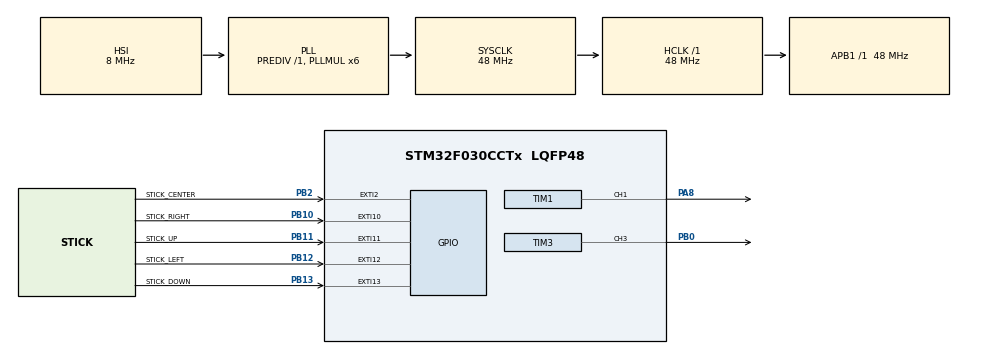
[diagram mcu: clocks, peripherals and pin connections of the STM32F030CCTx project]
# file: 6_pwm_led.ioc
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Mcu.Family=STM32F0
Mcu.Name=STM32F030CCTx
Mcu.Package=LQFP48
NVIC.EXTI2_3_IRQn=true\:0\:0\:false\:false\:true\:true\:true\:true
NVIC.EXTI4_15_IRQn=true\:0\:0\:false\:false\:true\:true\:true\:true
PA8.Signal=S_TIM1_CH1
PB0.Signal=S_TIM3_CH3
PB10.GPIO_Label=STICK_RIGHT
PB10.Signal=GPXTI10
PB11.GPIO_Label=STICK_UP
PB11.Signal=GPXTI11
PB12.GPIO_Label=STICK_LEFT
PB12.Signal=GPXTI12
PB13.GPIO_Label=STICK_DOWN
PB13.Signal=GPXTI13
PB2.GPIO_Label=STICK_CENTER
PB2.Signal=GPXTI2
ProjectManager.HeapSize=0x200
ProjectManager.StackSize=0x400
ProjectManager.TargetToolchain=CMake
RCC.AHBFreq_Value=48000000
RCC.APB1Freq_Value=48000000
RCC.APB1TimFreq_Value=48000000
RCC.HCLKFreq_Value=48000000
RCC.PLLMUL=RCC_PLL_MUL6
RCC.SYSCLKFreq_VALUE=48000000
RCC.SYSCLKSource=RCC_SYSCLKSOURCE_PLLCLK
SH.S_TIM1_CH1.0=TIM1_CH1,PWM Generation1 CH1
SH.S_TIM3_CH3.0=TIM3_CH3,PWM Generation3 CH3
TIM1.Channel-PWM\ Generation1\ CH1=TIM_CHANNEL_1
TIM3.Channel-PWM\ Generation3\ CH3=TIM_CHANNEL_3
TIM3.Period=665
TIM3.Prescaler=3
TIM3.Pulse-PWM\ Generation3\ CH3=665
VP_TIM3_VS_ClockSourceINT.Mode=Internal
board=custom

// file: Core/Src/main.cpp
/* USER CODE BEGIN Header */
/**
  ******************************************************************************
  * @file           : main.c
  * @brief          : Main program body
  ******************************************************************************
  * @attention
  *
  * Copyright (c) 2024 STMicroelectronics.
  * All rights reserved.
  *
  * This software is licensed under terms that can be found in the LICENSE file
  * in the root directory of this software component.
  * If no LICENSE file comes with this software, it is provided AS-IS.
  *
  ******************************************************************************
  */
/* USER CODE END Header */
#include "main.h"
#include "led_dimmer.h"

TIM_HandleTypeDef htim1;
TIM_HandleTypeDef htim3;

/* USER CODE BEGIN PV */
TIM_OC_InitTypeDef sConfigOC;
/* USER CODE END PV */

void SystemClock_Config(void);
static void MX_GPIO_Init(void);
static void MX_TIM1_Init(void);
static void MX_TIM3_Init(void);

int main(void)
{

  /* MCU Configuration--------------------------------------------------------*/

  /* Reset of all peripherals, Initializes the Flash interface and the Systick. */
  HAL_Init();

  /* Configure the system clock */
  SystemClock_Config();

  /* Initialize all configured peripherals */
  MX_GPIO_Init();
  MX_TIM1_Init();
  MX_TIM3_Init();
  /* USER CODE BEGIN 2 */
  // start PWM
  if (HAL_TIM_PWM_Start(&htim3, TIM_CHANNEL_3) != HAL_OK)
      Error_Handler();
  if (HAL_TIM_PWM_Start(&htim1, TIM_CHANNEL_2) != HAL_OK)
      Error_Handler();
  /* USER CODE END 2 */

  /* Infinite loop */
  /* USER CODE BEGIN WHILE */

  /*
   * For lab testing, set lab_mode to true
   * To change the duty cycle to n %, set a breakpoint at the while loop below this comment and modify
   * config->Pulse to (n / 100)*665 when the program is running.
   * Whithin CLion, this can be done by selecting the Pulse field and pressing F2.
   * Resume the program and wait 2 seconds to apply the new value.
  */
   volatile TIM_OC_InitTypeDef * volatile config = &sConfigOC;
   bool lab_mode = false;

  while (1)
  {
    /* USER CODE END WHILE */
    if(lab_mode) {
        HAL_Delay(2000);
        if (HAL_TIM_OC_ConfigChannel(&htim1, &sConfigOC, TIM_CHANNEL_2) != HAL_OK)
            Error_Handler();
    } else {
        // the mode is controlled and changed with the interrupt handler
        if(currentMode == 1) {
            auto_brightness();
        } else if(currentMode == 2) {
            heartbeat();
        }
    }

  }
}

void SystemClock_Config(void)
{
  RCC_OscInitTypeDef RCC_OscInitStruct = {0};
  RCC_ClkInitTypeDef RCC_ClkInitStruct = {0};

  /** Initializes the RCC Oscillators according to the specified parameters
  * in the RCC_OscInitTypeDef structure.
  */
  RCC_OscInitStruct.OscillatorType = RCC_OSCILLATORTYPE_HSI;
  RCC_OscInitStruct.HSIState = RCC_HSI_ON;
  RCC_OscInitStruct.HSICalibrationValue = RCC_HSICALIBRATION_DEFAULT;
  RCC_OscInitStruct.PLL.PLLState = RCC_PLL_ON;
  RCC_OscInitStruct.PLL.PLLSource = RCC_PLLSOURCE_HSI;
  RCC_OscInitStruct.PLL.PLLMUL = RCC_PLL_MUL6;
  RCC_OscInitStruct.PLL.PREDIV = RCC_PREDIV_DIV1;
  if (HAL_RCC_OscConfig(&RCC_OscInitStruct) != HAL_OK)
  {
    Error_Handler();
  }

  /** Initializes the CPU, AHB and APB buses clocks
  */
  RCC_ClkInitStruct.ClockType = RCC_CLOCKTYPE_HCLK|RCC_CLOCKTYPE_SYSCLK
                              |RCC_CLOCKTYPE_PCLK1;
  RCC_ClkInitStruct.SYSCLKSource = RCC_SYSCLKSOURCE_PLLCLK;
  RCC_ClkInitStruct.AHBCLKDivider = RCC_SYSCLK_DIV1;
  RCC_ClkInitStruct.APB1CLKDivider = RCC_HCLK_DIV1;

  if (HAL_RCC_ClockConfig(&RCC_ClkInitStruct, FLASH_LATENCY_1) != HAL_OK)
  {
    Error_Handler();
  }
}

static void MX_TIM1_Init(void)
{

  TIM_ClockConfigTypeDef sClockSourceConfig = {0};
  TIM_MasterConfigTypeDef sMasterConfig = {0};
  //TIM_OC_InitTypeDef sConfigOC = {0};
  TIM_BreakDeadTimeConfigTypeDef sBreakDeadTimeConfig = {0};

  htim1.Instance = TIM1;
  htim1.Init.Prescaler = 3;
  htim1.Init.CounterMode = TIM_COUNTERMODE_UP;
  htim1.Init.Period = 665;
  htim1.Init.ClockDivision = TIM_CLOCKDIVISION_DIV1;
  htim1.Init.RepetitionCounter = 0;
  htim1.Init.AutoReloadPreload = TIM_AUTORELOAD_PRELOAD_ENABLE;
  if (HAL_TIM_Base_Init(&htim1) != HAL_OK)
  {
    Error_Handler();
  }
  sClockSourceConfig.ClockSource = TIM_CLOCKSOURCE_INTERNAL;
  if (HAL_TIM_ConfigClockSource(&htim1, &sClockSourceConfig) != HAL_OK)
  {
    Error_Handler();
  }
  if (HAL_TIM_PWM_Init(&htim1) != HAL_OK)
  {
    Error_Handler();
  }
  sMasterConfig.MasterOutputTrigger = TIM_TRGO_RESET;
  sMasterConfig.MasterSlaveMode = TIM_MASTERSLAVEMODE_DISABLE;
  if (HAL_TIMEx_MasterConfigSynchronization(&htim1, &sMasterConfig) != HAL_OK)
  {
    Error_Handler();
  }
  sConfigOC.OCMode = TIM_OCMODE_PWM1;
  sConfigOC.Pulse = 665;
  sConfigOC.OCPolarity = TIM_OCPOLARITY_HIGH;
  sConfigOC.OCNPolarity = TIM_OCNPOLARITY_HIGH;
  sConfigOC.OCFastMode = TIM_OCFAST_DISABLE;
  sConfigOC.OCIdleState = TIM_OCIDLESTATE_RESET;
  sConfigOC.OCNIdleState = TIM_OCNIDLESTATE_RESET;
  if (HAL_TIM_PWM_ConfigChannel(&htim1, &sConfigOC, TIM_CHANNEL_2) != HAL_OK)
  {
    Error_Handler();
  }
  sBreakDeadTimeConfig.OffStateRunMode = TIM_OSSR_DISABLE;
  sBreakDeadTimeConfig.OffStateIDLEMode = TIM_OSSI_DISABLE;
  sBreakDeadTimeConfig.LockLevel = TIM_LOCKLEVEL_OFF;
  sBreakDeadTimeConfig.DeadTime = 0;
  sBreakDeadTimeConfig.BreakState = TIM_BREAK_DISABLE;
  sBreakDeadTimeConfig.BreakPolarity = TIM_BREAKPOLARITY_HIGH;
  sBreakDeadTimeConfig.AutomaticOutput = TIM_AUTOMATICOUTPUT_DISABLE;
  if (HAL_TIMEx_ConfigBreakDeadTime(&htim1, &sBreakDeadTimeConfig) != HAL_OK)
  {
    Error_Handler();
  }
  HAL_TIM_MspPostInit(&htim1);

}

static void MX_TIM3_Init(void)
{

  TIM_ClockConfigTypeDef sClockSourceConfig = {0};
  TIM_MasterConfigTypeDef sMasterConfig = {0};
  // TIM_OC_InitTypeDef sConfigOC = {0};

  htim3.Instance = TIM3;
  htim3.Init.Prescaler = 3;
  htim3.Init.CounterMode = TIM_COUNTERMODE_UP;
  htim3.Init.Period = 665;
  htim3.Init.ClockDivision = TIM_CLOCKDIVISION_DIV1;
  htim3.Init.AutoReloadPreload = TIM_AUTORELOAD_PRELOAD_ENABLE;
  if (HAL_TIM_Base_Init(&htim3) != HAL_OK)
  {
    Error_Handler();
  }
  sClockSourceConfig.ClockSource = TIM_CLOCKSOURCE_INTERNAL;
  if (HAL_TIM_ConfigClockSource(&htim3, &sClockSourceConfig) != HAL_OK)
  {
    Error_Handler();
  }
  if (HAL_TIM_PWM_Init(&htim3) != HAL_OK)
  {
    Error_Handler();
  }
  sMasterConfig.MasterOutputTrigger = TIM_TRGO_RESET;
  sMasterConfig.MasterSlaveMode = TIM_MASTERSLAVEMODE_DISABLE;
  if (HAL_TIMEx_MasterConfigSynchronization(&htim3, &sMasterConfig) != HAL_OK)
  {
    Error_Handler();
  }
  sConfigOC.OCMode = TIM_OCMODE_PWM1;
  sConfigOC.Pulse = 665;
  sConfigOC.OCPolarity = TIM_OCPOLARITY_HIGH;
  sConfigOC.OCFastMode = TIM_OCFAST_DISABLE;
  if (HAL_TIM_PWM_ConfigChannel(&htim3, &sConfigOC, TIM_CHANNEL_3) != HAL_OK)
  {
    Error_Handler();
  }
  HAL_TIM_MspPostInit(&htim3);

}

static void MX_GPIO_Init(void)
{
  GPIO_InitTypeDef GPIO_InitStruct = {0};

  /* GPIO Ports Clock Enable */
  __HAL_RCC_GPIOB_CLK_ENABLE();
  __HAL_RCC_GPIOA_CLK_ENABLE();

  /*Configure GPIO pins : STICK_CENTER_Pin STICK_RIGHT_Pin STICK_UP_Pin STICK_LEFT_Pin
                           STICK_DOWN_Pin */
  GPIO_InitStruct.Pin = STICK_CENTER_Pin|STICK_RIGHT_Pin|STICK_UP_Pin|STICK_LEFT_Pin
                          |STICK_DOWN_Pin;
  GPIO_InitStruct.Mode = GPIO_MODE_IT_RISING;
  GPIO_InitStruct.Pull = GPIO_NOPULL;
  HAL_GPIO_Init(GPIOB, &GPIO_InitStruct);

  /* EXTI interrupt init*/
  HAL_NVIC_SetPriority(EXTI2_3_IRQn, 0, 0);
  HAL_NVIC_EnableIRQ(EXTI2_3_IRQn);

  HAL_NVIC_SetPriority(EXTI4_15_IRQn, 0, 0);
  HAL_NVIC_EnableIRQ(EXTI4_15_IRQn);

}

void Error_Handler(void)
{
  __disable_irq();
  while (1)
  {
  }
}
